# CC23x0 register map
File version: 1.1
CPU: CM0+ r0p4, little endian, no MPU, no FPU, VTOR, 3 interrupt priority bits
Registers are 32-bit, read-write, reset 0x0 unless marked. A register's access mark holds for its fields unless they carry their own. Offsets are from the block's base; [hi:lo] are bit positions; {n}, {i} and the like mark numbered series; 'fields as' and 'values as' point back to an identical list.

## LRFDRXF
Base 0x40081C00
0x00 RXD — RX FIFO data. When written the register data is pushed to the RX FIFO. When read, data is popped from the RX FIFO
  [31:0] DATA — RX FIFO data. When written the register data is pushed to the RX FIFO. When read, data is popped from the RX FIFO. When writing or reading this register the access size will determine how many bytes are pushed to or popped from the FIFO. It is possible to push or pop 1,2 or 4 bytes depending on the access being done.

## LRFDS2R
Base 0x40085000
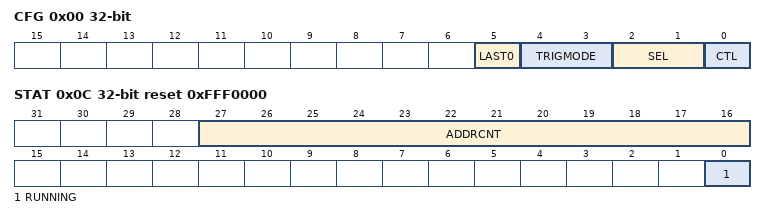
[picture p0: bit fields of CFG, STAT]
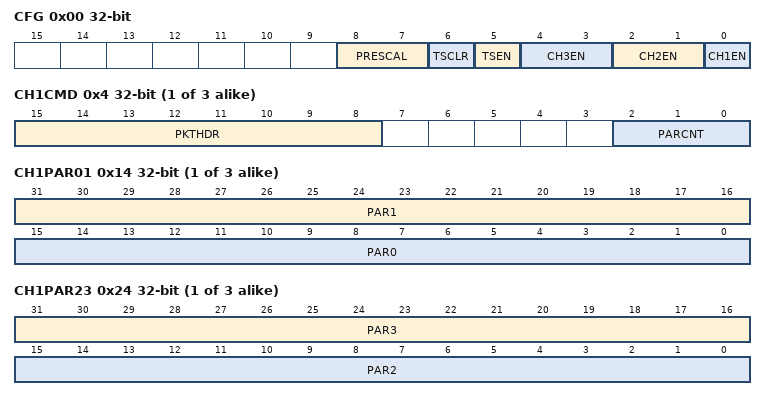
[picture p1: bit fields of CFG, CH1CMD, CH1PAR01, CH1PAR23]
0x00 CFG — Internal. Only to be used through TI provided API.
  [5] LAST0 — Internal. Only to be used through TI provided API.
    1=EN (Internal. Only to be used through TI provided API.); 0=DIS (Internal. Only to be used through TI provided API.)
  [4:3] TRIGMODE — Internal. Only to be used through TI provided API.
    2=ONEVENT (Internal. Only to be used through TI provided API.); 1=PERIODIC (Internal. Only to be used through TI provided API.); 0=ONESHOT (Internal. Only to be used through TI provided API.)
  [2:1] SEL — Internal. Only to be used through TI provided API.
    3=DECSTAGE (Internal. Only to be used through TI provided API.); 2=FRONTEND (Internal. Only to be used through TI provided API.); 1=ADCDIG (Internal. Only to be used through TI provided API.); 0=SYNTH (Internal. Only to be used through TI provided API.)
  [0] CTL — Internal. Only to be used through TI provided API.
    values as LAST0
0x04 START — Internal. Only to be used through TI provided API.
  [12:0] ADDR
    0x1FFF=ALLONES (Internal. Only to be used through TI provided API.); 0=ALLZEROS (Internal. Only to be used through TI provided API.)
0x08 STOP — Internal. Only to be used through TI provided API.
  fields as START
0x0C STAT ro reset 0xFFF0000 — Internal. Only to be used through TI provided API.
  [27:16] ADDRCNT — Internal. Only to be used through TI provided API.
    0xFFF=ALLONES (Internal. Only to be used through TI provided API.); 0=ALLZEROS (Internal. Only to be used through TI provided API.)
  [0] RUNNING — Internal. Only to be used through TI provided API.
    1=TRUE (Internal. Only to be used through TI provided API.); 0=FALSE (Internal. Only to be used through TI provided API.)
0x10 TRIG wo — Internal. Only to be used through TI provided API.
  [0] TRIG
    1=ARM (Internal. Only to be used through TI provided API.); 0=NO_EFFECT (Internal. Only to be used through TI provided API.)

## LRFDTRC
Base 0x40084000
0x00 CFG — Internal. Only to be used through TI provided API.
  [8:7] PRESCAL — Internal. Only to be used through TI provided API.
    {v}=DIV{v+1} (Internal. Only to be used through TI provided API.) (v=0..3)
  [6] TSCLR wo — Internal. Only to be used through TI provided API.
    1=ONE (Internal. Only to be used through TI provided API.); 0=ZERO (Internal. Only to be used through TI provided API.)
  [5] TSEN — Internal. Only to be used through TI provided API.
    1=ON (Internal. Only to be used through TI provided API.); 0=OFF (Internal. Only to be used through TI provided API.)
  [4:3] CH3EN — Internal. Only to be used through TI provided API.
    2=TOPSM (Internal. Only to be used through TI provided API.); 1=NORM (Internal. Only to be used through TI provided API.); 0=OFF (Internal. Only to be used through TI provided API.)
  [2:1] CH2EN — Internal. Only to be used through TI provided API.
    values as CH3EN
  [0] CH1EN — Internal. Only to be used through TI provided API.
    1=NORM (Internal. Only to be used through TI provided API.); 0=OFF (Internal. Only to be used through TI provided API.)
{0x0+4i} CH{i}CMD (i=1..3) — Internal. Only to be used through TI provided API.
  [15:8] PKTHDR — Internal. Only to be used through TI provided API.
    255=ALLONES (Internal. Only to be used through TI provided API.); 0=ALLZEROS (Internal. Only to be used through TI provided API.)
  [2:0] PARCNT — Internal. Only to be used through TI provided API.
    7=ALLONES (Internal. Only to be used through TI provided API.); 0=ALLZEROS (Internal. Only to be used through TI provided API.)
{0x10+4i} CH{i}PAR01 (i=1..3) — Internal. Only to be used through TI provided API.
  [31:16] PAR1 — Internal. Only to be used through TI provided API.
    0xFFFF=ALLONES (Internal. Only to be used through TI provided API.); 0=ALLZEROS (Internal. Only to be used through TI provided API.)
  [15:0] PAR0 — Internal. Only to be used through TI provided API.
    values as PAR1
{0x20+4i} CH{i}PAR23 (i=1..3) — Internal. Only to be used through TI provided API.
  [31:16] PAR3 — Internal. Only to be used through TI provided API.
    values as CH1PAR01.PAR1
  [15:0] PAR2 — Internal. Only to be used through TI provided API.
    values as CH1PAR01.PAR1
